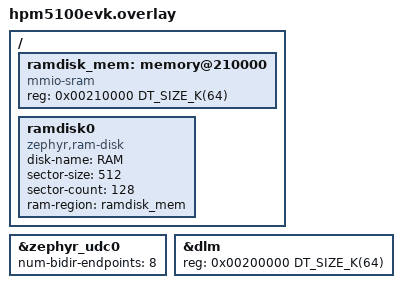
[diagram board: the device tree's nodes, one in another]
/*
 * Copyright 2026 HPMicro
 * SPDX-License-Identifier: Apache-2.0
 */

&zephyr_udc0 {
	status = "okay";
	num-bidir-endpoints = <8>;
};

/*
 * Keep system RAM on 32KB HRAM (unchanged board policy).
 * Carve 64KB from DLM for the RAM disk so Windows can FAT-format it.
 * (Default sample ramdisk is 96KB in HRAM and does not fit.)
 */
&dlm {
	/* First 64KB remains available as DTCM if referenced. */
	reg = <0x00200000 DT_SIZE_K(64)>;
};

/ {
	ramdisk_mem: memory@210000 {
		compatible = "mmio-sram";
		reg = <0x00210000 DT_SIZE_K(64)>;
	};

	ramdisk0 {
		compatible = "zephyr,ram-disk";
		disk-name = "RAM";
		sector-size = <512>;
		sector-count = <128>;
		ram-region = <&ramdisk_mem>;
	};
};
